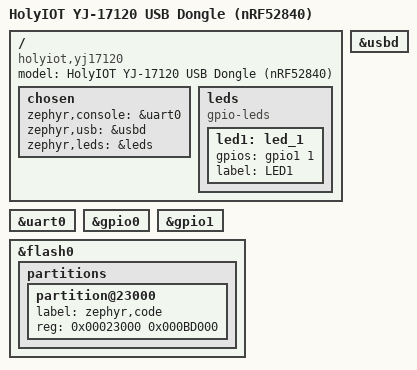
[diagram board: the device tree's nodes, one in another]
/dts-v1/;

#include <nordic/nrf52840.dtsi>

/ {
    model = "HolyIOT YJ-17120 USB Dongle (nRF52840)";
    compatible = "holyiot,yj17120";

    chosen {
        zephyr,console = &uart0;
        zephyr,usb = &usbd;
        zephyr,leds = &leds;
    };

    leds: leds {
        compatible = "gpio-leds";

        led1: led_1 {
            gpios = <&gpio1 1 GPIO_ACTIVE_HIGH>; /* P1.01 */
            label = "LED1";
        };
    };
};

/* USB Device */
&usbd {
    status = "okay";
};

/* UART (optional debug) */
&uart0 {
    status = "okay";
};

/* GPIO controllers */
&gpio0 { status = "okay"; };
&gpio1 { status = "okay"; };

/*
 * Flash partitions
 * MBR:        0x00000000 - 0x00000FFF
 * SoftDevice: 0x00001000 - 0x00022FFF
 * App:        0x00023000 - 0x000DFFFF
 * Bootloader: 0x000E0000 - 0x000FDFFF
 */

&flash0 {
    partitions {
        partition@23000 {
            label = "zephyr,code";
            reg = <0x00023000 0x000BD000>;
        };
    };
};

